# NUC1311AE_v1 register map
File version: 1.0
Registers are 32-bit, read-write, reset 0x0 unless marked. A register's access mark holds for its fields unless they carry their own. Offsets are from the block's base; [hi:lo] are bit positions.

## WDT — WDT Register Map
Base 0x40004000
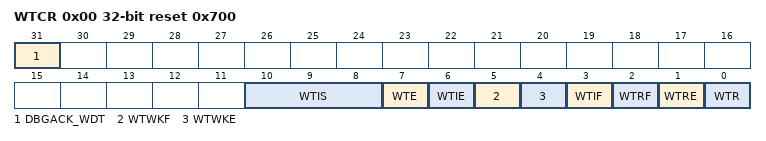
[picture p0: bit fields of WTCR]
0x00 WTCR reset 0x700 — Watchdog Timer Control Register
  [31] DBGACK_WDT — ICE Debug Mode Acknowledge Disable Control (Write Protect). WDT up counter will keep going no matter CPU is held by ICE or not.
    0=ICE debug mode acknowledgement effects WDT counting; 1=ICE debug mode acknowledgement Disabled
  [10:8] WTIS — Watchdog Timer Time-Out Interval Selection (Write Protect). These three bits select the time-out interval period for the WDT.
    0=24 *TWDT; 1=26 * TWDT; 2=28 * TWDT; 3=210 * TWDT; 4=212 * TWDT; 5=214 * TWDT; 6=216 * TWDT; 7=218 * TWDT
  [7] WTE — Watchdog Timer Enable Control (Write Protect). Note: If CWDTEN (CONFIG0[31] Watchdog Enable) bit is set to 0, this bit is forced as 1 and user cannot change this bit to 0.
    0=WDT Disabled. (This action will reset the internal up counter value.); 1=WDT Enabled
  [6] WTIE — Watchdog Timer Time-Out Interrupt Enable Control (Write Protect). If this bit is enabled, the WDT time-out interrupt signal is generated and inform to CPU.
    0=WDT time-out interrupt Disabled; 1=WDT time-out interrupt Enabled
  [5] WTWKF — Watchdog Timer Time-Out Wake-Up Flag. This bit indicates the interrupt wake-up flag status of WDT. Note: This bit is cleared by writing 1 to it.
    0=WDT does not cause chip wake-up; 1=Chip wake-up from Idle or Power-down mode if WDT time-out interrupt signal generated
  [4] WTWKE — Watchdog Timer Time-Out Wake-Up Function Control (Write Protect). If this bit is set to 1, while WTIF is generated to 1 and WTIE enabled, the WDT time-out interrupt signal will generate a wake-up trigger event to chip. Note: Chip can be woken-up by WDT time-out interrupt signal generated only if WDT clock source is selected to 10 kHz oscillator.
    0=Wake-up trigger event Disabled if WDT time-out interrupt signal generated; 1=Wake-up trigger event Enabled if WDT time-out interrupt signal generated
  [3] WTIF — Watchdog Timer Time-Out Interrupt Flag. This bit will set to 1 while WDT up counter value reaches the selected WDT time-out interval. Note: This bit is cleared by writing 1 to it.
    0=WDT time-out interrupt did not occur; 1=WDT time-out interrupt occurred
  [2] WTRF — Watchdog Timer Time-Out Reset Flag. This bit indicates the system has been reset by WDT time-out reset or not. Note: This bit is cleared by writing 1 to it.
    0=WDT time-out reset did not occur; 1=WDT time-out reset occurred
  [1] WTRE — Watchdog Timer Reset Enable Control (Write Protect). Setting this bit will enable the WDT time-out reset function if the WDT up counter value has not been cleared after the specific WDT reset delay period expires.
    0=WDT time-out reset function Disabled; 1=WDT time-out reset function Enabled
  [0] WTR — Reset Watchdog Timer Up Counter (Write Protect). Note: This bit will be automatically cleared by hardware.
    0=No effect; 1=Reset the internal 18-bit WDT up counter value
0x04 WTCRALT — Watchdog Timer Alternative Control Register
  [1:0] WTRDSEL — Watchdog Timer Reset Delay Selection (Write Protect). When WDT time-out happened, user has a time named WDT Reset Delay Period to clear WDT counter to prevent WDT time-out reset happened. User can select a suitable value of WDT Reset Delay Period for different WDT time-out period. These bits are protected bit. It means programming this bit needs to write '59h', '16h', '88h' to address 0x5000_0100 to disable register protection. Reference the register REGWRPROT at address GCR_BA+0x100. Note: This register will be reset to 0 if WDT time-out reset happened.
    0=Watchdog Timer Reset Delay Period is 1026 * WDT_CLK; 1=Watchdog Timer Reset Delay Period is 130 * WDT_CLK; 2=Watchdog Timer Reset Delay Period is 18 * WDT_CLK; 3=Watchdog Timer Reset Delay Period is 3 * WDT_CLK
